# XHSC_HC32L12X register map
Vendor: XHSC Co.Ltd; Series: ARMCM0P; File version: 1.0
CPU: CM0P r0p0, little endian, no MPU, no FPU, 3 interrupt priority bits
Registers are 32-bit, read-write, reset 0x0 unless marked. A register's access mark holds for its fields unless they carry their own. Offsets are from the block's base; [hi:lo] are bit positions; 'fields as' and 'values as' point back to an identical list.

## SYSCTRL
Base 0x40021800
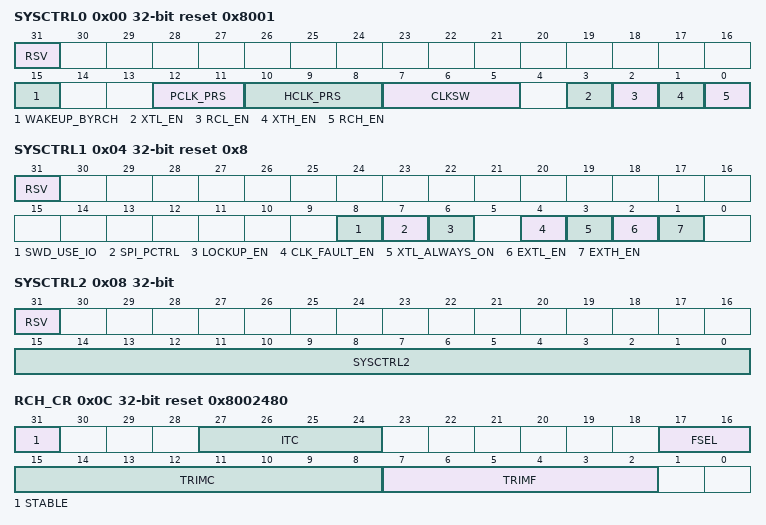
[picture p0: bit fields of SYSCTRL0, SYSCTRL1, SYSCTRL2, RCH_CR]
0x00 SYSCTRL0 reset 0x8001 (reset mask 0x9FEF)
  [31] RSV, [15] WAKEUP_BYRCH, [12:11] PCLK_PRS, [10:8] HCLK_PRS, [7:5] CLKSW, [3] XTL_EN, [2] RCL_EN, [1] XTH_EN, [0] RCH_EN
0x04 SYSCTRL1 reset 0x8 (reset mask 0x1DE)
  [31] RSV, [8] SWD_USE_IO, [7] SPI_PCTRL, [6] LOCKUP_EN, [4] CLK_FAULT_EN, [3] XTL_ALWAYS_ON, [2] EXTL_EN, [1] EXTH_EN
0x08 SYSCTRL2 wo (reset mask 0xFFFF)
  [31] RSV rw, [15:0] SYSCTRL2
0x0C RCH_CR reset 0x8002480 (reset mask 0x1F03FFFC)
  [31] STABLE ro, [27:24] ITC, [17:16] FSEL, [15:8] TRIMC, [7:2] TRIMF
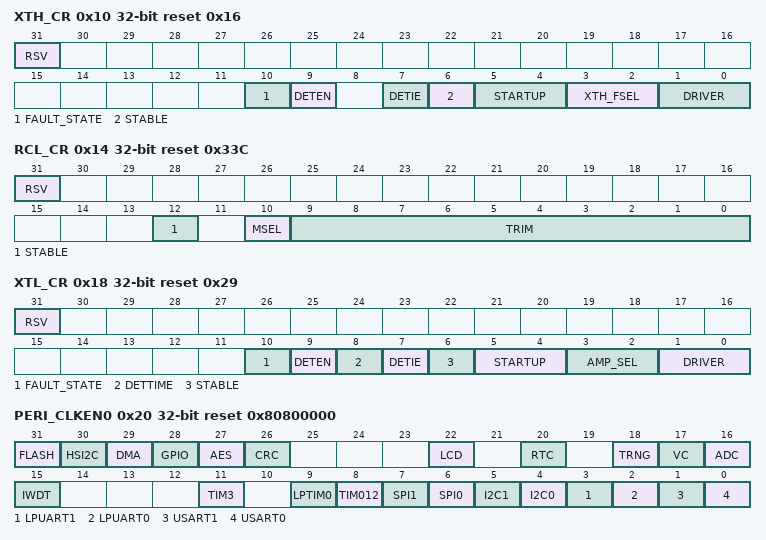
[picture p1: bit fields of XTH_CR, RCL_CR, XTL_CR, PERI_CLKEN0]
0x10 XTH_CR reset 0x16 (reset mask 0xFF)
  [31] RSV, [10] FAULT_STATE, [9] DETEN, [7] DETIE, [6] STABLE ro, [5:4] STARTUP, [3:2] XTH_FSEL, [1:0] DRIVER
0x14 RCL_CR reset 0x33C (reset mask 0x17FF)
  [31] RSV, [12] STABLE ro, [10] MSEL, [9:0] TRIM
0x18 XTL_CR reset 0x29 (reset mask 0x7FF)
  [31] RSV, [10] FAULT_STATE, [9] DETEN, [8] DETTIME, [7] DETIE, [6] STABLE ro, [5:4] STARTUP, [3:2] AMP_SEL, [1:0] DRIVER
0x20 PERI_CLKEN0 reset 0x80800000
  [31] FLASH, [30] HSI2C, [29] DMA, [28] GPIO, [27] AES, [26] CRC, [22] LCD, [20] RTC, [18] TRNG, [17] VC, [16] ADC, [15] IWDT, [11] TIM3, [9] LPTIM0, [8] TIM012, [7] SPI1, [6] SPI0, [5] I2C1, [4] I2C0, [3] LPUART1, [2] LPUART0, [1] USART1, [0] USART0
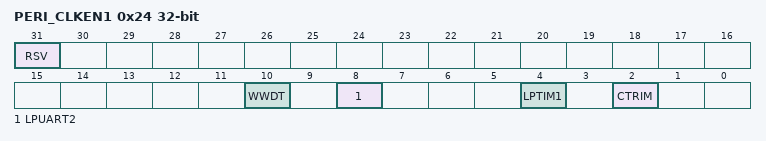
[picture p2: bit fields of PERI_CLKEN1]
0x24 PERI_CLKEN1 (reset mask 0x514)
  [31] RSV, [10] WWDT, [8] LPUART2, [4] LPTIM1, [2] CTRIM

## TIM0_MODE0
Base 0x40003000
Same registers: TIM1_MODE0 0x40003400, TIM2_MODE0 0x40003800, TIM3_MODE0 0x40009800
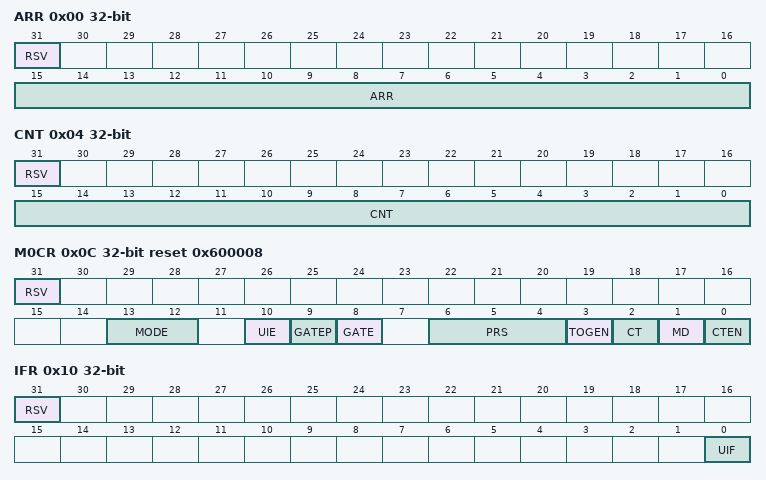
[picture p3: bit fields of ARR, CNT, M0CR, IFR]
0x00 ARR (reset mask 0xFFFF)
  [31] RSV, [15:0] ARR
0x04 CNT (reset mask 0xFFFF)
  [31] RSV, [15:0] CNT
0x08 CNT32
0x0C M0CR reset 0x600008 (reset mask 0x377C)
  [31] RSV, [13:12] MODE, [10] UIE, [9] GATEP, [8] GATE, [6:4] PRS, [3] TOGEN, [2] CT, [1] MD, [0] CTEN
0x10 IFR ro (reset mask 0x1)
  [31] RSV rw, [0] UIF
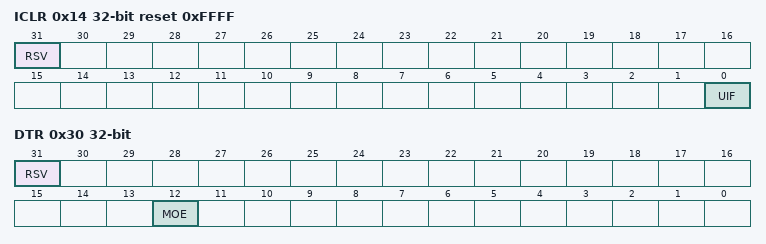
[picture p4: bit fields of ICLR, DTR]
0x14 ICLR wo reset 0xFFFF (reset mask 0x1)
  [31] RSV rw, [0] UIF
0x30 DTR (reset mask 0x1000)
  [31] RSV, [12] MOE

## TIM0_MODE1
Base 0x40003000; alternate view of TIM0_MODE0
Same registers: TIM1_MODE1 0x40003400 (alternate view of TIM1_MODE0), TIM2_MODE1 0x40003800 (alternate view of TIM2_MODE0), TIM3_MODE1 0x40009800 (alternate view of TIM3_MODE0)
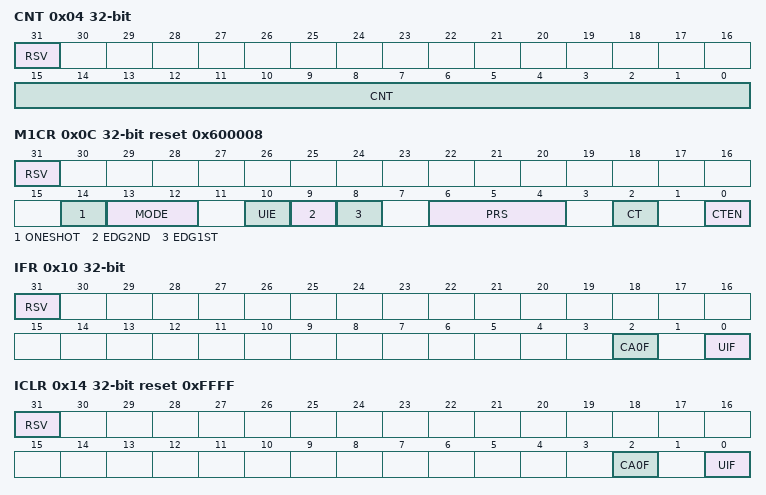
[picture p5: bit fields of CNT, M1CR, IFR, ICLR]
0x04 CNT (reset mask 0xFFFF)
  [31] RSV, [15:0] CNT
0x0C M1CR reset 0x600008 (reset mask 0x7775)
  [31] RSV, [14] ONESHOT, [13:12] MODE, [10] UIE, [9] EDG2ND, [8] EDG1ST, [6:4] PRS, [2] CT, [0] CTEN
0x10 IFR ro (reset mask 0x5)
  [31] RSV rw, [2] CA0F, [0] UIF
0x14 ICLR wo reset 0xFFFF (reset mask 0x5)
  [31] RSV rw, [2] CA0F, [0] UIF
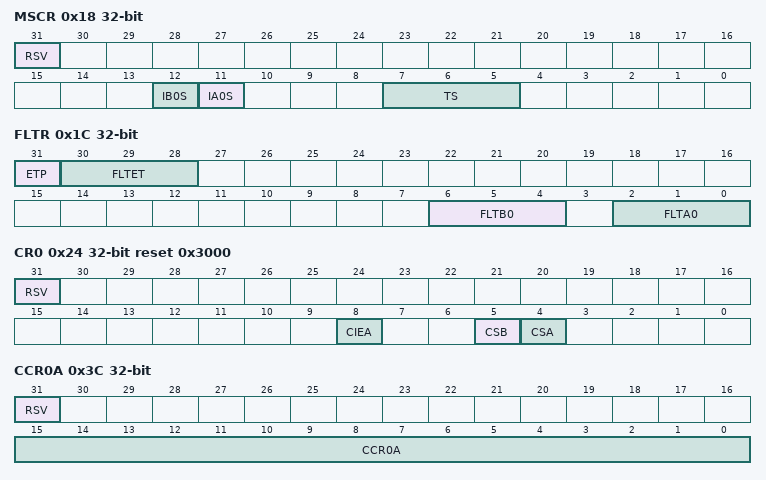
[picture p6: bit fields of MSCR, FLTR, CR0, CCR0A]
0x18 MSCR (reset mask 0x18E0)
  [31] RSV, [12] IB0S, [11] IA0S, [7:5] TS
0x1C FLTR
  [31] ETP, [30:28] FLTET, [6:4] FLTB0, [2:0] FLTA0
0x24 CR0 reset 0x3000 (reset mask 0x130)
  [31] RSV, [8] CIEA, [5] CSB, [4] CSA
0x3C CCR0A (reset mask 0xFFFF)
  [31] RSV, [15:0] CCR0A

## TIM0_MODE23
Base 0x40003000; alternate view of TIM0_MODE0
Same registers: TIM1_MODE23 0x40003400 (alternate view of TIM1_MODE0), TIM2_MODE23 0x40003800 (alternate view of TIM2_MODE0)
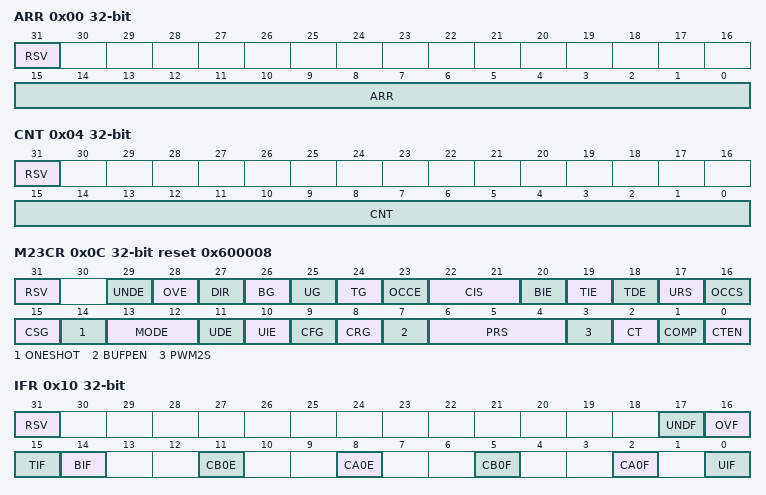
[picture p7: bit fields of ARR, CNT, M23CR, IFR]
0x00 ARR (reset mask 0xFFFF)
  [31] RSV, [15:0] ARR
0x04 CNT (reset mask 0xFFFF)
  [31] RSV, [15:0] CNT
0x0C M23CR reset 0x600008 (reset mask 0x3FFFFFFF)
  [31] RSV, [29] UNDE, [28] OVE, [27] DIR, [26] BG wo, [25] UG wo, [24] TG wo, [23] OCCE, [22:21] CIS, [20] BIE, [19] TIE, [18] TDE, [17] URS, [16] OCCS, [15] CSG, [14] ONESHOT, [13:12] MODE, [11] UDE, [10] UIE, [9] CFG, [8] CRG, [7] BUFPEN, [6:4] PRS, [3] PWM2S, [2] CT, [1] COMP, [0] CTEN
0x10 IFR ro (reset mask 0x3C925)
  [31] RSV, [17] UNDF, [16] OVF, [15] TIF, [14] BIF, [11] CB0E, [8] CA0E, [5] CB0F, [2] CA0F, [0] UIF
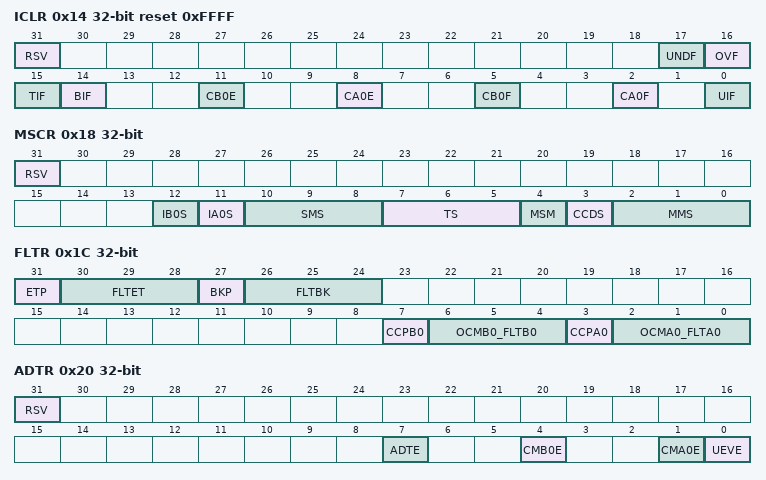
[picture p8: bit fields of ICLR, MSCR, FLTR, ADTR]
0x14 ICLR wo reset 0xFFFF (reset mask 0x3C925)
  fields as IFR
0x18 MSCR (reset mask 0x1FFF)
  [31] RSV, [12] IB0S, [11] IA0S, [10:8] SMS, [7:5] TS, [4] MSM, [3] CCDS, [2:0] MMS
0x1C FLTR
  [31] ETP, [30:28] FLTET, [27] BKP, [26:24] FLTBK, [7] CCPB0, [6:4] OCMB0_FLTB0, [3] CCPA0, [2:0] OCMA0_FLTA0
0x20 ADTR (reset mask 0x93)
  [31] RSV, [7] ADTE, [4] CMB0E, [1] CMA0E, [0] UEVE
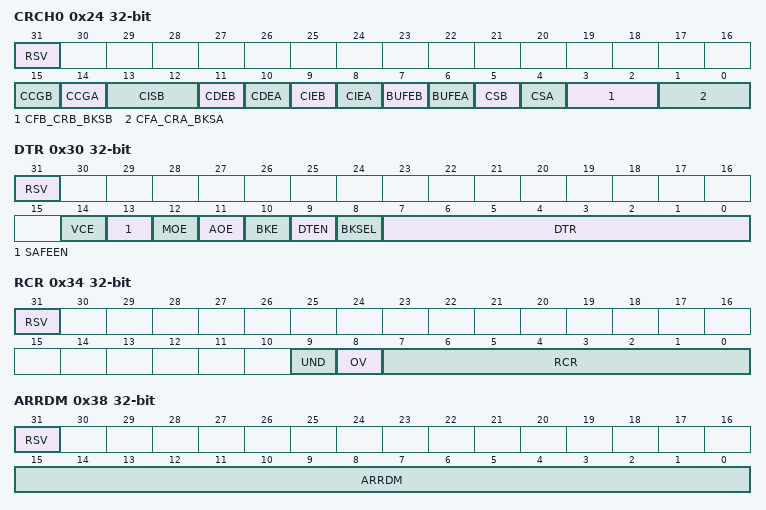
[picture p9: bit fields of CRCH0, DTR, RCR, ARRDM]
0x24 CRCH0 (reset mask 0xFFFF)
  [31] RSV, [15] CCGB, [14] CCGA, [13:12] CISB, [11] CDEB, [10] CDEA, [9] CIEB, [8] CIEA, [7] BUFEB, [6] BUFEA, [5] CSB, [4] CSA, [3:2] CFB_CRB_BKSB, [1:0] CFA_CRA_BKSA
0x30 DTR (reset mask 0x7FFF)
  [31] RSV, [14] VCE, [13] SAFEEN, [12] MOE, [11] AOE, [10] BKE, [9] DTEN, [8] BKSEL, [7:0] DTR
0x34 RCR (reset mask 0x3FF)
  [31] RSV, [9] UND, [8] OV, [7:0] RCR
0x38 ARRDM (reset mask 0xFFFF)
  [31] RSV, [15:0] ARRDM
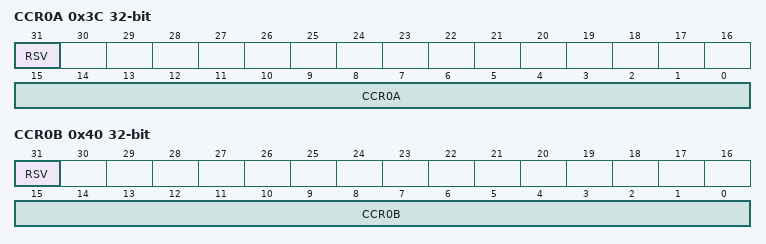
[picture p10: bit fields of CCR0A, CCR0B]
0x3C CCR0A (reset mask 0xFFFF)
  [31] RSV, [15:0] CCR0A
0x40 CCR0B (reset mask 0xFFFF)
  [31] RSV, [15:0] CCR0B
